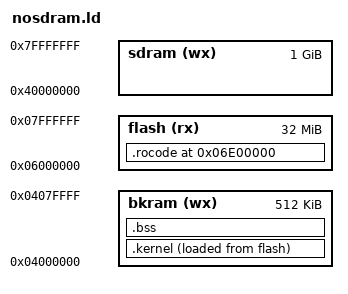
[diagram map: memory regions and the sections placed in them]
/*******************************************************************************
*
* Filename:	nosdram.ld
* {{{
* Project:	10Gb Ethernet switch
*
* Computer Generated: This file is computer generated by AUTOFPGA. DO NOT EDIT.
* DO NOT EDIT THIS FILE!
*
* CmdLine:	autofpga -I .: -d -o . allclocks.txt siclk.txt sirefclk.txt global.txt wbdown.txt icape.txt version.txt pwrcount.txt rtccount.txt gpio.txt spio.txt wbuconsole.txt zipmaster.txt bkram.txt ddr3.txt flash.txt sdio.txt emmc.txt sdslave.txt sata.txt netrouter.txt cpunet.txt netstats.txt busscope.txt routescope.txt i2cscope.txt gatescope.txt netscope.txt sdioscope.txt emmcscope.txt flashscope.txt satascope.txt zipscope.txt mem_bkram_only.txt mem_sdram_only.txt mem_flash_bkram.txt mem_full.txt mem_bootrom_bkram.txt i2ccpu.txt fan.txt sirefclkcounter.txt netclk.txt
*
* Creator:	Dan Gisselquist, Ph.D.
*		Gisselquist Technology, LLC
*
/*******************************************************************************
* }}}
* Copyright (C) 2023-2026, Gisselquist Technology, LLC
* {{{
* This file is part of the ETH10G project.
*
* The ETH10G project contains free software and gateware, licensed under the
* terms of the 3rd version of the GNU General Public License as published by
* the Free Software Foundation.
*
* This project is distributed in the hope that it will be useful, but WITHOUT
* ANY WARRANTY; without even the implied warranty of MERCHANTIBILITY or
* FITNESS FOR A PARTICULAR PURPOSE.  See the GNU General Public License
* for more details.
*
* You should have received a copy of the GNU General Public License along
* with this program.  (It's in the $(ROOT)/doc directory.  Run make with no
* target there if the PDF file isn't present.)  If not, see
* <http://www.gnu.org/licenses/> for a copy.
* }}}
* License:	GPL, v3, as defined and found on www.gnu.org,
* {{{
*		http://www.gnu.org/licenses/gpl.html
*
/*******************************************************************************
*
* }}}
*/
ENTRY(_start)

MEMORY
{
	/* To be listed here, a slave must be of type MEMORY.  If the slave
	* has a defined name in its @LD.NAME tag, it will be listed here
	* under that name, otherwise it will be listed under it's
	* @$(PREFIX) tag with an underscore prepended to it.  The permissions
	* are given by the @LD.PERM tag.  Allowable permissions include
	* 'r' (read only), 'rx' (read and execute, but no writes),
	* 'wx' (read, write, and execute).  If no permission tag exists, a
	* permission of 'r' will be assumed.
	*/
	   bkram(wx) : ORIGIN = 0x04000000, LENGTH = 0x00080000
	   flash(rx) : ORIGIN = 0x06000000, LENGTH = 0x02000000
	   sdram(wx) : ORIGIN = 0x40000000, LENGTH = 0x40000000
}

/* For each defined memory peripheral, we also define a pointer to that
* memory.  The name of this pointer is given by the @LD.NAME tag within
* the memory peripheral's configuration
*/
_bkram    = ORIGIN(bkram);
_flash    = ORIGIN(flash);
_sdram    = ORIGIN(sdram);
/* LD.DEFNS from mem_flash_bkram */
_kram  = 0; /* No high-speed kernel RAM */
_ram   = ORIGIN(bkram);
_rom   = ORIGIN(flash);
_top_of_stack = ORIGIN(bkram) + LENGTH(bkram);


_rtccount = 0x02000b58;
_pwrcount = 0x02000b54;
_uart = 0x02000780;
/* LD.SCRIPT from mem_flash_bkram */
SECTIONS
{
       .rocode 0x06e00000 : ALIGN(4) {
               _boot_address = .;
               *(.start) *(.boot)
               *(.text.startup)
               *(.text*)
               *(.rodata*) *(.strings)
       } > flash
       _kram_start = . ;
       _kram_end = . ;
       _ram_image_start = . ;
       .kernel : ALIGN_WITH_INPUT {
               *(.kernel)
               *(.data) *(COMMON)
               }> bkram AT> flash
       _ram_image_end = . ;
       .bss : ALIGN_WITH_INPUT {
               *(.bss)
               _bss_image_end = . ;
               } > bkram
       _top_of_heap = .;
}

